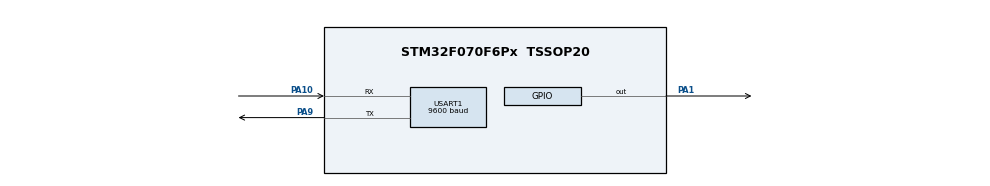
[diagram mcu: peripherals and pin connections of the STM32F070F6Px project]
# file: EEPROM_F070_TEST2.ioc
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Mcu.Family=STM32F0
Mcu.Name=STM32F070F6Px
Mcu.Package=TSSOP20
PA1.Signal=GPIO_Output
PA10.Mode=Asynchronous
PA10.Signal=USART1_RX
PA9.Mode=Asynchronous
PA9.Signal=USART1_TX
ProjectManager.HeapSize=0x200
ProjectManager.StackSize=0x400
ProjectManager.TargetToolchain=STM32CubeIDE
USART1.BaudRate=9600
USART1.VirtualMode=VM_ASYNC
board=custom

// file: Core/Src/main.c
/* USER CODE BEGIN Header */
/**
  ******************************************************************************
  * @file           : main.c
  * @brief          : Main program body
  ******************************************************************************
  * @attention
  *
  * Copyright (c) 2023 STMicroelectronics.
  * All rights reserved.
  *
  * This software is licensed under terms that can be found in the LICENSE file
  * in the root directory of this software component.
  * If no LICENSE file comes with this software, it is provided AS-IS.
  *
  ******************************************************************************
  */
/* USER CODE END Header */
#include "main.h"

/* USER CODE BEGIN Includes */
#include "eeprom_emulated.h"
#include <stdio.h>
#include <string.h>

/* USER CODE END Includes */

/* USER CODE BEGIN PD */
#define DATA1_ADDR  0x08007000

/* USER CODE END PD */

UART_HandleTypeDef huart1;

void SystemClock_Config(void);
static void MX_GPIO_Init(void);
static void MX_USART1_UART_Init(void);

/* USER CODE BEGIN 0 */
uint16_t flag;

/* USER CODE END 0 */

int main(void)
{

  /* MCU Configuration--------------------------------------------------------*/

  /* Reset of all peripherals, Initializes the Flash interface and the Systick. */
  HAL_Init();

  /* Configure the system clock */
  SystemClock_Config();

  /* Initialize all configured peripherals */
  MX_GPIO_Init();
  MX_USART1_UART_Init();
  /* USER CODE BEGIN 2 */

  uint32_t data1 = 100;

  // Print the data to be written using UART
    printf("Data to be written to EEPROM:\r\n");
    printf("Data1: %lu\r\n", data1);

    if (Flash_Write_Data(DATA1_ADDR, &data1, sizeof(data1) / 4) == HAL_OK) {

    	  flag = 1;
    	  printf("flag = %d\r",flag);
          printf("Data written to EEPROM successfully.\r\n");
        } else {
          flag = 2;
          printf("flag2 = %d\r",flag);
          printf("Error writing data to EEPROM.\r\n");
        }

    HAL_Delay(1000);

      uint32_t readData1;
       Flash_Read_Data(DATA1_ADDR, &readData1, sizeof(readData1) / 4);

       // Toggle LED when data is successfully read
//       if (readData1 == data1) {
//         printf("Data read from EEPROM successfully.\r\n");
//         HAL_GPIO_TogglePin(GPIOA, GPIO_PIN_1);
//         HAL_Delay(1000);
//
//       } else {
//         printf("Error reading data from EEPROM.\r\n");
//       }

//      // Print the read data using UART
//	 printf("Data read from EEPROM:\r\n");
//	 printf("Data1: %lu\r\n", readData1);

  /* USER CODE END 2 */

  /* Infinite loop */
  /* USER CODE BEGIN WHILE */
  while (1)
  {

	  if (readData1 == data1) {
	   flag = 3;
	   printf("flag3 = %d\r",flag);
	   printf("Data read from EEPROM successfully.\r\n");
	   HAL_GPIO_TogglePin(GPIOA, GPIO_PIN_1);
	   HAL_Delay(1000);

	 } else {
	   flag = 4;
	   printf("flag4 = %d\r",flag);
	   printf("Error reading data from EEPROM.\r\n");
	 }

	 // Use sprintf to format the data and store it in a character array
	char buffer[100];
	sprintf(buffer, "Data read from EEPROM:\r\nData1: %lu\r\n", readData1);

	// Transmit the data over UART
	HAL_UART_Transmit(&huart1, (uint8_t*)buffer, strlen(buffer), HAL_MAX_DELAY);
    /* USER CODE END WHILE */

  }
}

void SystemClock_Config(void)
{
  RCC_OscInitTypeDef RCC_OscInitStruct = {0};
  RCC_ClkInitTypeDef RCC_ClkInitStruct = {0};
  RCC_PeriphCLKInitTypeDef PeriphClkInit = {0};

  /** Initializes the RCC Oscillators according to the specified parameters
  * in the RCC_OscInitTypeDef structure.
  */
  RCC_OscInitStruct.OscillatorType = RCC_OSCILLATORTYPE_HSI;
  RCC_OscInitStruct.HSIState = RCC_HSI_ON;
  RCC_OscInitStruct.HSICalibrationValue = RCC_HSICALIBRATION_DEFAULT;
  RCC_OscInitStruct.PLL.PLLState = RCC_PLL_NONE;
  if (HAL_RCC_OscConfig(&RCC_OscInitStruct) != HAL_OK)
  {
    Error_Handler();
  }

  /** Initializes the CPU, AHB and APB buses clocks
  */
  RCC_ClkInitStruct.ClockType = RCC_CLOCKTYPE_HCLK|RCC_CLOCKTYPE_SYSCLK
                              |RCC_CLOCKTYPE_PCLK1;
  RCC_ClkInitStruct.SYSCLKSource = RCC_SYSCLKSOURCE_HSI;
  RCC_ClkInitStruct.AHBCLKDivider = RCC_SYSCLK_DIV1;
  RCC_ClkInitStruct.APB1CLKDivider = RCC_HCLK_DIV1;

  if (HAL_RCC_ClockConfig(&RCC_ClkInitStruct, FLASH_LATENCY_0) != HAL_OK)
  {
    Error_Handler();
  }
  PeriphClkInit.PeriphClockSelection = RCC_PERIPHCLK_USART1;
  PeriphClkInit.Usart1ClockSelection = RCC_USART1CLKSOURCE_PCLK1;
  if (HAL_RCCEx_PeriphCLKConfig(&PeriphClkInit) != HAL_OK)
  {
    Error_Handler();
  }
}

static void MX_USART1_UART_Init(void)
{

  huart1.Instance = USART1;
  huart1.Init.BaudRate = 9600;
  huart1.Init.WordLength = UART_WORDLENGTH_8B;
  huart1.Init.StopBits = UART_STOPBITS_1;
  huart1.Init.Parity = UART_PARITY_NONE;
  huart1.Init.Mode = UART_MODE_TX_RX;
  huart1.Init.HwFlowCtl = UART_HWCONTROL_NONE;
  huart1.Init.OverSampling = UART_OVERSAMPLING_16;
  huart1.Init.OneBitSampling = UART_ONE_BIT_SAMPLE_DISABLE;
  huart1.AdvancedInit.AdvFeatureInit = UART_ADVFEATURE_NO_INIT;
  if (HAL_UART_Init(&huart1) != HAL_OK)
  {
    Error_Handler();
  }

}

static void MX_GPIO_Init(void)
{
  GPIO_InitTypeDef GPIO_InitStruct = {0};

  /* GPIO Ports Clock Enable */
  __HAL_RCC_GPIOA_CLK_ENABLE();

  /*Configure GPIO pin Output Level */
  HAL_GPIO_WritePin(GPIOA, GPIO_PIN_1, GPIO_PIN_RESET);

  /*Configure GPIO pin : PA1 */
  GPIO_InitStruct.Pin = GPIO_PIN_1;
  GPIO_InitStruct.Mode = GPIO_MODE_OUTPUT_PP;
  GPIO_InitStruct.Pull = GPIO_NOPULL;
  GPIO_InitStruct.Speed = GPIO_SPEED_FREQ_LOW;
  HAL_GPIO_Init(GPIOA, &GPIO_InitStruct);

}

void Error_Handler(void)
{
  __disable_irq();
  while (1)
  {
  }
}
